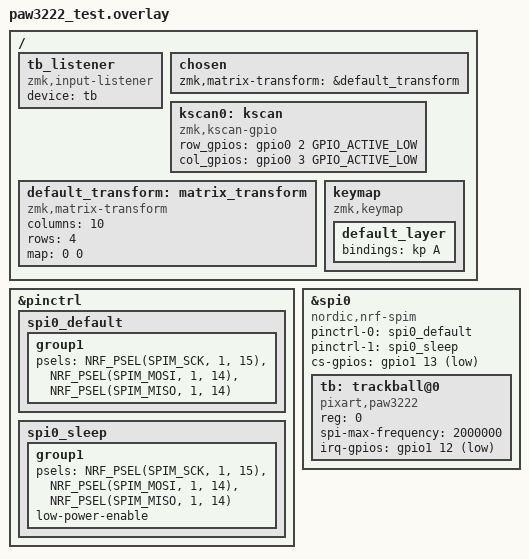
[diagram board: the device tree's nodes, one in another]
#include <dt-bindings/zmk/matrix_transform.h>
#include <behaviors.dtsi>

/ {
    tb_listener: tb_listener {
        compatible = "zmk,input-listener";
        status = "okay";
        device = <&tb>;
    };

    // *********** ビルドのために必要 ************
    chosen {
        zmk,matrix-transform = &default_transform;
    };

    kscan0: kscan {
        compatible = "zmk,kscan-gpio";
        row_gpios = <&gpio0 2 GPIO_ACTIVE_LOW>;
        col_gpios = <&gpio0 3 GPIO_ACTIVE_LOW>;
    };

    default_transform: matrix_transform {
        compatible = "zmk,matrix-transform";
        columns = <10>;
        rows = <4>; 
        map = <0 0>;
    };

    keymap {
        compatible = "zmk,keymap";
        default_layer {
            bindings = < &kp A >;
        };
    };
    // ****************************************
};

&pinctrl {
    spi0_default: spi0_default {
        group1 {
            psels = <NRF_PSEL(SPIM_SCK, 1, 15)>,
                    <NRF_PSEL(SPIM_MOSI, 1, 14)>,
                    <NRF_PSEL(SPIM_MISO, 1, 14)>;
        };
    };

    spi0_sleep: spi0_sleep {
        group1 {
            psels = <NRF_PSEL(SPIM_SCK, 1, 15)>,
                    <NRF_PSEL(SPIM_MOSI, 1, 14)>,
                    <NRF_PSEL(SPIM_MISO, 1, 14)>;
            low-power-enable;
        };
    };
};

&spi0 {
    status = "okay";
    compatible = "nordic,nrf-spim";
    pinctrl-0 = <&spi0_default>;
    pinctrl-1 = <&spi0_sleep>;
    pinctrl-names = "default", "sleep";
    cs-gpios = <&gpio1 13 GPIO_ACTIVE_LOW>;

    tb: trackball@0 {
        status = "okay";
        compatible = "pixart,paw3222";
        reg = <0>;
        spi-max-frequency = <2000000>;
        irq-gpios = <&gpio1 12 (GPIO_ACTIVE_LOW | GPIO_PULL_UP)>;
    };
};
